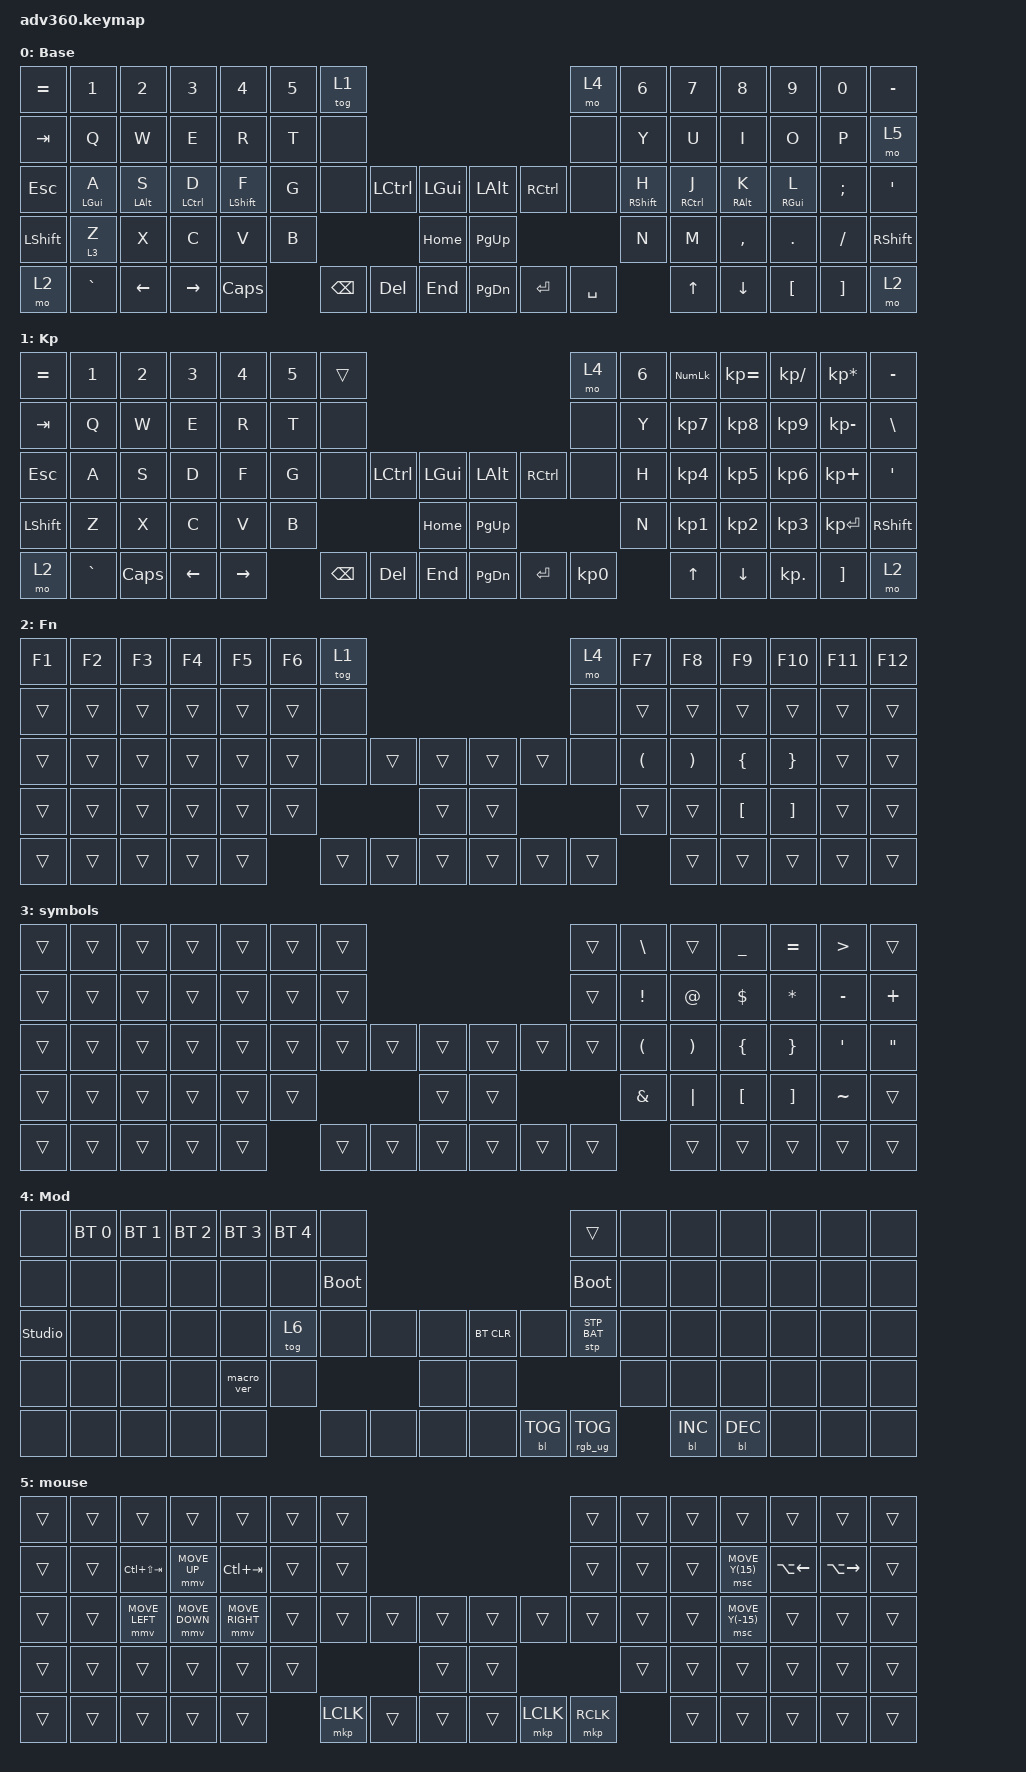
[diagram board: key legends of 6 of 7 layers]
#include <dt-bindings/zmk/stp.h>

#define ZMK_POINTING_DEFAULT_MOVE_VAL 1500
#define ZMK_POINTING_DEFAULT_SCRL_VAL 20

#include <behaviors.dtsi>
#include <dt-bindings/zmk/backlight.h>
#include <dt-bindings/zmk/bt.h>
#include <dt-bindings/zmk/keys.h>
#include <dt-bindings/zmk/pointing.h>
#include <dt-bindings/zmk/rgb.h>

/ {
    behaviors {
        #include "macros.dtsi"
      #include "version.dtsi"

        hm: homerow_mods {
            compatible = "zmk,behavior-hold-tap";
            label = "HOMEROW_MODS";
            #binding-cells = <2>;
            tapping-term-ms = <200>;
            quick_tap_ms = <175>;
            flavor = "tap-preferred";
            bindings = <&kp>, <&kp>;
        };
    };

    keymap {
        compatible = "zmk,keymap";

        default_layer {
            display-name = "Base";
            bindings = <
&kp EQUAL   &kp N1          &kp N2          &kp N3       &kp N4            &kp N5  &tog 1                                                      &mo 4      &kp N6             &kp N7       &kp N8           &kp N9           &kp N0    &kp MINUS
&kp TAB     &kp Q           &kp W           &kp E        &kp R             &kp T   &none                                                       &none      &kp Y              &kp U        &kp I            &kp O            &kp P     &mo 5
&kp ESCAPE  &hm LEFT_GUI A  &hm LEFT_ALT S  &hm LCTRL D  &hm LEFT_SHIFT F  &kp G   &none     &kp LCTRL  &kp LGUI      &kp LEFT_ALT  &kp RCTRL  &none      &hm RIGHT_SHIFT H  &hm RCTRL J  &hm RIGHT_ALT K  &hm RIGHT_GUI L  &kp SEMI  &kp SQT
&kp LSHFT   &lt 3 Z         &kp X           &kp C        &kp V             &kp B                        &kp HOME      &kp PG_UP                           &kp N              &kp M        &kp COMMA        &kp DOT          &kp FSLH  &kp RSHFT
&mo 2       &kp GRAVE       &kp LEFT        &kp RIGHT    &kp CAPSLOCK              &kp BSPC  &kp DEL    &kp END       &kp PG_DN     &kp ENTER  &kp SPACE                     &kp UP       &kp DOWN         &kp LBKT         &kp RBKT  &mo 2
            >;
        };

        keypad {
            display-name = "Kp";
            bindings = <
&kp EQUAL  &kp N1     &kp N2    &kp N3    &kp N4     &kp N5  &trans                                                      &mo 4      &kp N6  &kp KP_NUM  &kp KP_EQUAL  &kp KP_DIVIDE  &kp KP_MULTIPLY  &kp MINUS
&kp TAB    &kp Q      &kp W     &kp E     &kp R      &kp T   &none                                                       &none      &kp Y   &kp KP_N7   &kp KP_N8     &kp KP_N9      &kp KP_MINUS     &kp BSLH
&kp ESC    &kp A      &kp S     &kp D     &kp F      &kp G   &none     &kp LCTRL  &kp LGUI      &kp LEFT_ALT  &kp RCTRL  &none      &kp H   &kp KP_N4   &kp KP_N5     &kp KP_N6      &kp KP_PLUS      &kp SQT
&kp LSHFT  &kp Z      &kp X     &kp C     &kp V      &kp B                        &kp HOME      &kp PG_UP                           &kp N   &kp KP_N1   &kp KP_N2     &kp KP_N3      &kp KP_ENTER     &kp RSHFT
&mo 2      &kp GRAVE  &kp CAPS  &kp LEFT  &kp RIGHT          &kp BSPC  &kp DEL    &kp END       &kp PG_DN     &kp ENTER  &kp KP_N0          &kp UP      &kp DOWN      &kp KP_DOT     &kp RBKT         &mo 2
            >;
        };

        fn {
            display-name = "Fn";
            bindings = <
&kp F1  &kp F2  &kp F3  &kp F4  &kp F5  &kp F6  &tog 1                                      &mo 4   &kp F7                &kp F8                 &kp F9            &kp F10            &kp F11  &kp F12
&trans  &trans  &trans  &trans  &trans  &trans  &none                                       &none   &trans                &trans                 &trans            &trans             &trans   &trans
&trans  &trans  &trans  &trans  &trans  &trans  &none   &trans  &trans      &trans  &trans  &none   &kp LEFT_PARENTHESIS  &kp RIGHT_PARENTHESIS  &kp LEFT_BRACE    &kp RIGHT_BRACE    &trans   &trans
&trans  &trans  &trans  &trans  &trans  &trans                  &trans      &trans                  &trans                &trans                 &kp LEFT_BRACKET  &kp RIGHT_BRACKET  &trans   &trans
&trans  &trans  &trans  &trans  &trans          &trans  &trans  &trans      &trans  &trans  &trans                        &trans                 &trans            &trans             &trans   &trans
            >;
        };

        symbols {
            bindings = <
&trans  &trans  &trans  &trans  &trans  &trans  &trans                                      &trans  &kp BACKSLASH         &trans                 &kp UNDER         &kp EQUAL          &kp GREATER_THAN  &trans
&trans  &trans  &trans  &trans  &trans  &trans  &trans                                      &trans  &kp EXCLAMATION       &kp AT_SIGN            &kp DOLLAR        &kp ASTERISK       &kp MINUS         &kp PLUS
&trans  &trans  &trans  &trans  &trans  &trans  &trans  &trans  &trans      &trans  &trans  &trans  &kp LEFT_PARENTHESIS  &kp RIGHT_PARENTHESIS  &kp LEFT_BRACE    &kp RIGHT_BRACE    &kp SQT           &kp DOUBLE_QUOTES
&trans  &trans  &trans  &trans  &trans  &trans                  &trans      &trans                  &kp AMPERSAND         &kp PIPE               &kp LEFT_BRACKET  &kp RIGHT_BRACKET  &kp TILDE         &trans
&trans  &trans  &trans  &trans  &trans          &trans  &trans  &trans      &trans  &trans  &trans                        &trans                 &trans            &trans             &trans            &trans
            >;
        };

        mod {
            display-name = "Mod";
            bindings = <
&none           &bt BT_SEL 0  &bt BT_SEL 1  &bt BT_SEL 2  &bt BT_SEL 3  &bt BT_SEL 4  &none                                                  &trans           &none  &none       &none       &none  &none  &none
&none           &none         &none         &none         &none         &none         &bootloader                                            &bootloader      &none  &none       &none       &none  &none  &none
&studio_unlock  &none         &none         &none         &none         &tog 6        &none        &none  &none      &bt BT_CLR  &none       &stp STP_BAT     &none  &none       &none       &none  &none  &none
&none           &none         &none         &none         &macro_ver    &none                             &none      &none                                    &none  &none       &none       &none  &none  &none
&none           &none         &none         &none         &none                       &none        &none  &none      &none       &bl BL_TOG  &rgb_ug RGB_TOG         &bl BL_INC  &bl BL_DEC  &none  &none  &none
            >;
        };

        mouse {
            bindings = <
&trans  &trans  &trans           &trans          &trans           &trans  &trans                                            &trans     &trans  &trans  &trans            &trans              &trans         &trans
&trans  &trans  &kp LC(LS(TAB))  &mmv MOVE_UP    &kp LC(TAB)      &trans  &trans                                            &trans     &trans  &trans  &msc MOVE_Y(15)   &kp LA(LEFT_ARROW)  &kp LA(RIGHT)  &trans
&trans  &trans  &mmv MOVE_LEFT   &mmv MOVE_DOWN  &mmv MOVE_RIGHT  &trans  &trans     &trans  &trans      &trans  &trans     &trans     &trans  &trans  &msc MOVE_Y(-15)  &trans              &trans         &trans
&trans  &trans  &trans           &trans          &trans           &trans                     &trans      &trans                        &trans  &trans  &trans            &trans              &trans         &trans
&trans  &trans  &trans           &trans          &trans                   &mkp LCLK  &trans  &trans      &trans  &mkp LCLK  &mkp RCLK          &trans  &trans            &trans              &trans         &trans
            >;
        };

        gaming {
            display-name = "Game";
            bindings = <
&trans  &trans  &trans  &trans  &trans  &trans  &trans                                      &trans  &trans  &trans  &trans  &trans  &trans  &trans
&trans  &trans  &trans  &trans  &trans  &trans  &trans                                      &trans  &trans  &trans  &trans  &trans  &trans  &trans
&trans  &kp A   &kp S   &kp D   &kp F   &trans  &trans  &trans  &trans      &trans  &trans  &trans  &kp H   &kp J   &kp K   &kp L   &trans  &trans
&trans  &trans  &trans  &trans  &trans  &trans                  &trans      &trans                  &trans  &trans  &trans  &trans  &trans  &trans
&kp LCTRL  &trans  &trans  &trans  &trans          &trans  &trans  &trans      &trans  &trans  &trans                  &trans  &trans  &trans  &kp LCTRL
            >;
        };

        extra1 {
            display-name = "Red";
            status = "reserved";
        };

        extra2 {
            display-name = "Purple";
            status = "reserved";
        };

        extra3 {
            display-name = "Cyan";
            status = "reserved";
        };

        extra4 {
            display-name = "Yellow";
            status = "reserved";
        };
    };
};
